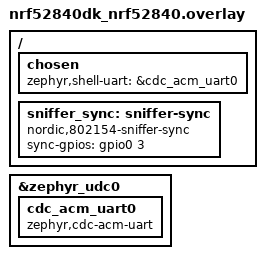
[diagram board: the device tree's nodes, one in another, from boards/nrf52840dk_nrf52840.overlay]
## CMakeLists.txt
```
#
# Copyright (c) 2023 Nordic Semiconductor
#
# SPDX-License-Identifier: LicenseRef-Nordic-5-Clause
#

cmake_minimum_required(VERSION 3.20.0)

list(APPEND DTS_ROOT ${CMAKE_CURRENT_SOURCE_DIR})

find_package(Zephyr REQUIRED HINTS $ENV{ZEPHYR_BASE})
project(802154_sniffer)

target_sources(app PRIVATE
	src/main.c
	src/sniffer_uart.c
)
```

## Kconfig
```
#
# Copyright (c) 2026 Nordic Semiconductor ASA
#
# SPDX-License-Identifier: LicenseRef-Nordic-5-Clause
#

mainmenu "IEEE 802.15.4 Sniffer sample"

config IEEE802154_SNIFFER_TIME_SYNC
	bool "Hardware GPIO time synchronization"
	select NRFX_GPIOTE
	select NRFX_GPPI
	# Only the nRF52 and nRF53 path drives the pulse from a TIMER instance,
	# nRF54L uses GRTC.
	select NRFX_TIMER if !SOC_SERIES_NRF54L
	default y if $(dt_nodelabel_enabled,sniffer_sync)
	help
	  Enable GPIOTE + PPI + GRTC/RTC capture based time sync between
	  multiple sniffer devices. Requires sniffer_sync devicetree node.

config IEEE802154_SNIFFER_SYNC_INTERVAL_MS
	int "Primary sync pulse interval (ms)"
	default 100
	range 10 60000
	depends on IEEE802154_SNIFFER_TIME_SYNC
	help
	  Interval between the sync pulses of the primary device. The lower bound
	  leaves room for the pulse to be cleared from a workqueue item before the
	  next one is due.

config IEEE802154_SNIFFER_SYNC_PULSE_US
	int "Primary sync pulse width (us)"
	default 10
	depends on IEEE802154_SNIFFER_TIME_SYNC
	help
	  Requested width of the sync pulse. Only the rising edge is generated in
	  hardware, while the pin is cleared from a workqueue item, so the pulse is
	  at least one system tick wide (about 30 us) regardless of this value.

config IEEE802154_SNIFFER_UART_BUFFER_SIZE
	int "Capture output buffer size (bytes)"
	default 131072
	help
	  Size of the ring buffer holding capture lines that are waiting for the
	  UART.

config IEEE802154_SNIFFER_UART_BUFFER_LARGE
	bool
	default y if IEEE802154_SNIFFER_UART_BUFFER_SIZE > 32767
	select RING_BUFFER_LARGE
	help
	  Ring buffers above 32 kB need 32 bit indices.

source "Kconfig.zephyr"
```

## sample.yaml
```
sample:
  description: IEEE 802.15.4 Sniffer sample
  name: IEEE 802.15.4 Sniffer
tests:
  sample.peripheral.802154_sniffer:
    sysbuild: true
    build_only: true
    integration_platforms:
      - nrf52840dk/nrf52840
      - nrf52840dongle/nrf52840
      - nrf54lm20dongle/nrf54lm20b/cpuapp
    platform_allow:
      - nrf52840dk/nrf52840
      - nrf52840dongle/nrf52840
      - nrf54lm20dongle/nrf54lm20b/cpuapp
    tags:
      - ci_build
      - sysbuild
      - ci_samples_peripheral_802154
  sample.peripheral.802154_sniffer.no_time_sync:
    sysbuild: true
    build_only: true
    extra_configs:
      - CONFIG_IEEE802154_SNIFFER_TIME_SYNC=n
    integration_platforms:
      - nrf52840dk/nrf52840
    platform_allow:
      - nrf52840dk/nrf52840
    tags:
      - ci_build
      - sysbuild
      - ci_samples_peripheral_802154
```

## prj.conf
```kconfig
# Enabling radio driver
CONFIG_NETWORKING=y
CONFIG_IEEE802154=y
CONFIG_IEEE802154_RAW_MODE=y
CONFIG_NET_PKT_TIMESTAMP=y

# Allow sharing the RTC between IEEE 802.15.4 and Zephyr
CONFIG_NRF_RTC_TIMER_USER_CHAN_COUNT=3

# Increase the number of RX buffers to minimize the chances of frame drops.
# The value must not be higher than 127 - X, where X is the number of notification
# slots reserved by the radio driver (see NTF_PRIMARY_POOL_SIZE macro definition).
CONFIG_NRF_802154_RX_BUFFERS=120

# Capture output encoding. Base64 needs a third fewer bytes than hex.
CONFIG_BASE64=y

# The capture buffer in sniffer_uart.c uses the ring buffer API directly.
CONFIG_RING_BUFFER=y

# Shell configuration
CONFIG_SHELL=y
CONFIG_SHELL_PROMPT_UART=""
CONFIG_SHELL_VT100_COLORS=n

# Sync lines are prioritized only while they sit in the sniffer ring buffer;
# once handed to the backend they queue behind the frame data in FIFO order.
# Keep this buffer small, so that it only has to keep the USB endpoint busy,
# and let the sniffer ring absorb the bursts.
CONFIG_SHELL_BACKEND_SERIAL_TX_RING_BUFFER_SIZE=2048

# Keep USB transfer handling off the system workqueue, which also runs the
# time sync reporting work.
CONFIG_USBD_CDC_ACM_WORKQUEUE=y

# The radio RX thread formats and queues every capture line, which needs more
# stack than the 800 bytes the driver defaults to.
CONFIG_IEEE802154_NRF5_RX_STACK_SIZE=2048

# LED indication
CONFIG_DK_LIBRARY=y

# USB configuration
CONFIG_UART_LINE_CTRL=y
CONFIG_SHELL_BACKEND_SERIAL_INIT_PRIORITY=51

CONFIG_USB_DEVICE_STACK_NEXT=y
CONFIG_CDC_ACM_SERIAL_INITIALIZE_AT_BOOT=y
CONFIG_CDC_ACM_SERIAL_MANUFACTURER_STRING="Nordic Semiconductor ASA"
CONFIG_CDC_ACM_SERIAL_PRODUCT_STRING="nRF 802154 Sniffer"
CONFIG_CDC_ACM_SERIAL_VID=0x1915
CONFIG_CDC_ACM_SERIAL_PID=0x154b

# Disable boot banner
CONFIG_BOOT_BANNER=n
CONFIG_NCS_BOOT_BANNER=n
```

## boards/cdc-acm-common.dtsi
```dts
/*
 * Copyright (c) 2026 Nordic Semiconductor ASA
 *
 * SPDX-License-Identifier: LicenseRef-Nordic-5-Clause
 *
 * Common CDC ACM UART properties, included by the board overlays.
 *
 * The TX FIFO is deliberately small: it is a strict FIFO, so every queued byte
 * delays the next sync report. Bursts are absorbed by the prioritized sniffer
 * ring buffer instead.
 */

hw-flow-control;
tx-fifo-size = <2048>;
```

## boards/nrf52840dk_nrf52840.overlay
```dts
/*
 * Copyright (c) 2023 Nordic Semiconductor ASA
 *
 * SPDX-License-Identifier: LicenseRef-Nordic-5-Clause
 */

/ {
	chosen {
		zephyr,shell-uart = &cdc_acm_uart0;
	};

	sniffer_sync: sniffer-sync {
		compatible = "nordic,802154-sniffer-sync";
		/* SYNC PIN: P0.03. */
		sync-gpios = <&gpio0 3 0>;
	};
};

&zephyr_udc0 {
	cdc_acm_uart0: cdc_acm_uart0 {
		compatible = "zephyr,cdc-acm-uart";
		#include "cdc-acm-common.dtsi"
	};
};
```

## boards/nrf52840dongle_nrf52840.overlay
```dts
/*
 * Copyright (c) 2026 Nordic Semiconductor ASA
 *
 * SPDX-License-Identifier: LicenseRef-Nordic-5-Clause
 */

/ {
	sniffer_sync: sniffer-sync {
		compatible = "nordic,802154-sniffer-sync";
		/* SYNC PIN: P0.02. */
		sync-gpios = <&gpio0 2 0>;
	};
};

&board_cdc_acm_uart {
	#include "cdc-acm-common.dtsi"
};
```

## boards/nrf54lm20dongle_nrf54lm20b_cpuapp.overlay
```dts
/*
 * Copyright (c) 2026 Nordic Semiconductor ASA
 *
 * SPDX-License-Identifier: LicenseRef-Nordic-5-Clause
 */

/ {
	sniffer_sync: sniffer-sync {
		compatible = "nordic,802154-sniffer-sync";
		/* SYNC PIN: P0.03. */
		sync-gpios = <&gpio0 3 0>;
	};
};

&board_cdc_acm_uart {
	#include "cdc-acm-common.dtsi"
};
```

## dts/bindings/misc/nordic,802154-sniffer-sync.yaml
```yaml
# Copyright (c) 2026 Nordic Semiconductor ASA
# SPDX-License-Identifier: LicenseRef-Nordic-5-Clause

description: GPIO pin used for hardware time sync between sniffers

compatible: "nordic,802154-sniffer-sync"

properties:
  sync-gpios:
    type: phandle-array
    required: true
    description: |
      GPIO used for the sync pulse (output on the primary device, input on a
      secondary one).

      Only the port and the pin number are used. The direction follows the role
      selected at runtime, while the pull and the polarity are fixed by the
      capture path (pull-down input, rising edge), so the flags cell is ignored.
```

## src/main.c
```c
/*
 * Copyright (c) 2023 Nordic Semiconductor ASA
 *
 * SPDX-License-Identifier: LicenseRef-Nordic-5-Clause
 */

#include <zephyr/kernel.h>
#include <zephyr/net/ieee802154_radio.h>
#include <zephyr/shell/shell.h>
#include <zephyr/sys/base64.h>
#include <zephyr/sys/util.h>
#include <nrf_802154.h>
#include <nrf_802154_const.h>
#include <stdlib.h>
#include <dk_buttons_and_leds.h>
#include "sniffer_uart.h"

#if IS_ENABLED(CONFIG_IEEE802154_SNIFFER_TIME_SYNC)
#include "time_sync.h"
#endif

#if defined(CONFIG_BOARD_NRF52840DONGLE)
#include <zephyr/drivers/gpio.h>
static const struct device *const gpio_dev = DEVICE_DT_GET(DT_NODELABEL(gpio0));
#endif

#define IEEE802154_FCS_LENGTH 2
#define MAX_PAYLOAD_SIZE (MAX_PACKET_SIZE - IEEE802154_FCS_LENGTH)

/* base64_encode() needs room for the padding and the terminator. */
#define PAYLOAD_STRING_LENGTH (4 * DIV_ROUND_UP(MAX_PAYLOAD_SIZE, 3) + 1)

/* "r " + payload + " -128" + " 255" + " " + 20 digits + CRLF. */
#define MAX_LINE_LENGTH (2 + (PAYLOAD_STRING_LENGTH - 1) + 5 + 4 + 21 + 2)
BUILD_ASSERT(MAX_LINE_LENGTH <= SNIFFER_UART_LINE_MAX,
	     "capture line does not fit in the sniffer UART line buffer");

/* The nRF54L radio reports the RX timestamp of a frame this many microseconds
 * earlier than the nRF52 one. The measured constant is added back so that
 * captures from both merge onto a single timeline.
 */
#define NRF54L_RX_TIMESTAMP_BIAS_US 10

static const struct device *radio_dev =
	DEVICE_DT_GET(DT_CHOSEN(zephyr_ieee802154));
static struct ieee802154_radio_api *radio_api;
static char payload_string[PAYLOAD_STRING_LENGTH];
static bool heartbeat_led_state;
static bool packet_led_state;
static k_timeout_t heartbeat_interval;

static void heartbeat(struct k_work *work);

static K_WORK_DELAYABLE_DEFINE(heartbeat_work, heartbeat);

static void heartbeat(struct k_work *work)
{
	ARG_UNUSED(work);

	heartbeat_led_state = !heartbeat_led_state;
	dk_set_led(DK_LED1, heartbeat_led_state);
	k_work_reschedule(&heartbeat_work, heartbeat_interval);
}

enum net_verdict ieee802154_handle_ack(struct net_if *iface,
				       struct net_pkt *pkt)
{
	ARG_UNUSED(iface);
	ARG_UNUSED(pkt);

	return NET_DROP;
}

int net_recv_data(struct net_if *iface, struct net_pkt *pkt)
{
	if (!pkt) {
		return -EINVAL;
	}

	if (net_pkt_is_empty(pkt)) {
		return -ENODATA;
	}

	uint8_t *psdu = net_buf_frag_last(pkt->buffer)->data;
	size_t length = net_buf_frags_len(pkt->buffer);
	uint8_t lqi = net_pkt_ieee802154_lqi(pkt);
	int8_t rssi = net_pkt_ieee802154_rssi_dbm(pkt);
	struct net_ptp_time *pkt_time = net_pkt_timestamp(pkt);
	uint64_t timestamp =
		pkt_time->second * USEC_PER_SEC + pkt_time->nanosecond / NSEC_PER_USEC;
	size_t encoded;

#if defined(CONFIG_SOC_SERIES_NRF54L)
	timestamp += NRF54L_RX_TIMESTAMP_BIAS_US;
#endif

	/* The radio has already verified the FCS and the host discards it, so it
	 * is not worth transmitting.
	 */
	if (length <= IEEE802154_FCS_LENGTH) {
		net_pkt_unref(pkt);
		return -EINVAL;
	}
	length -= IEEE802154_FCS_LENGTH;

	if (base64_encode(payload_string, sizeof(payload_string), &encoded, psdu, length) != 0) {
		net_pkt_unref(pkt);
		return -ENOMEM;
	}

	packet_led_state = !packet_led_state;
	dk_set_led(DK_LED4, packet_led_state);

	sniffer_uart_emit("r %s %d %u %llu", payload_string, rssi, lqi, timestamp);

	net_pkt_unref(pkt);

	return 0;
}

static int cmd_channel(const struct shell *shell, size_t argc, char **argv)
{
	uint32_t channel;
	int err;

	switch (argc) {
	case 1:
		shell_print(shell, "%d", nrf_802154_channel_get());
		break;
	case 2:
		channel = atoi(argv[1]);
		err = radio_api->set_channel(radio_dev, channel);
		if (err != 0) {
			shell_error(shell, "invalid channel: %s (use 11 to 26)", argv[1]);
			return err;
		}
		break;
	default:
		shell_print(shell, "invalid number of parameters: %d", argc);
		break;
	}

	return 0;
}
SHELL_CMD_ARG_REGISTER(channel, NULL, "Set radio channel", cmd_channel, 1, 1);

#if NRF_802154_GFSK_2MBPS_PHY_ENABLED
static int cmd_phy(const struct shell *shell, size_t argc, char **argv)
{
	ARG_UNUSED(argc);

	nrf_802154_phy_t phy;

	if (strcmp(argv[1], "2m") == 0) {
		phy = NRF_802154_PHY_EXP1_GFSK_2MBPS;
	} else if (strcmp(argv[1], "250k") == 0) {
		phy = NRF_802154_PHY_OQPSK_250KBPS;
	} else {
		shell_error(shell, "unknown phy: %s (use 2m or 250k)", argv[1]);
		return -EINVAL;
	}

	nrf_802154_phy_set(phy);

	return 0;
}

SHELL_CMD_ARG_REGISTER(phy, NULL, "Set radio PHY <2m|250k>", cmd_phy, 2, 0);
#endif /* NRF_802154_GFSK_2MBPS_PHY_ENABLED */

static int cmd_receive(const struct shell *shell, size_t argc, char **argv)
{
	ARG_UNUSED(shell);
	ARG_UNUSED(argc);
	ARG_UNUSED(argv);

	heartbeat_interval = K_MSEC(250);
	radio_api->start(radio_dev);

	return 0;
}
SHELL_CMD_ARG_REGISTER(receive, NULL, "Put radio in receive state", cmd_receive, 1, 0);

static int cmd_sleep(const struct shell *shell, size_t argc, char **argv)
{
	ARG_UNUSED(shell);
	ARG_UNUSED(argc);
	ARG_UNUSED(argv);

#if IS_ENABLED(CONFIG_IEEE802154_SNIFFER_TIME_SYNC)
	time_sync_stop();
#endif

	heartbeat_interval = K_SECONDS(1);
	radio_api->stop(radio_dev);

	return 0;
}
SHELL_CMD_ARG_REGISTER(sleep, NULL, "Disable the radio", cmd_sleep, 1, 0);

#if IS_ENABLED(CONFIG_IEEE802154_SNIFFER_TIME_SYNC)
static int cmd_sync_stop(const struct shell *shell, size_t argc, char **argv)
{
	ARG_UNUSED(argc);
	ARG_UNUSED(argv);

	time_sync_stop();
	shell_print(shell, "sync stopped");
	return 0;
}

static int cmd_sync_primary_start(const struct shell *shell, size_t argc, char **argv)
{
	uint32_t interval_ms = CONFIG_IEEE802154_SNIFFER_SYNC_INTERVAL_MS;
	int err = 0;

	if (argc >= 2) {
		interval_ms = (uint32_t)shell_strtoul(argv[1], 10, &err);
		if (err != 0) {
			shell_error(shell, "invalid interval: %s", argv[1]);
			return -EINVAL;
		}
	}

	err = time_sync_primary_start(interval_ms);
	if (err != 0) {
		shell_error(shell, "sync primary start failed: %d", err);
		return err;
	}

	shell_print(shell, "sync primary started interval_ms=%u", interval_ms);
	return 0;
}

static int cmd_sync_secondary(const struct shell *shell, size_t argc, char **argv)
{
	unsigned long sniffer_id = 1;
	int err = 0;

	if (argc >= 2) {
		sniffer_id = shell_strtoul(argv[1], 10, &err);
		if (err != 0 || sniffer_id > UINT8_MAX) {
			shell_error(shell, "invalid id: %s (use 0 to %u)", argv[1], UINT8_MAX);
			return -EINVAL;
		}
	}

	err = time_sync_secondary_start((uint8_t)sniffer_id);
	if (err != 0) {
		shell_error(shell, "sync secondary start failed: %d", err);
		return err;
	}

	shell_print(shell, "sync secondary started id=%u", (uint8_t)sniffer_id);
	return 0;
}

SHELL_STATIC_SUBCMD_SET_CREATE(
	sub_sync_primary,
	SHELL_CMD_ARG(start, NULL,
		      "sync primary start [interval_ms]",
		      cmd_sync_primary_start, 1, 1),
	SHELL_SUBCMD_SET_END);

SHELL_STATIC_SUBCMD_SET_CREATE(
	sub_sync,
	SHELL_CMD(primary, &sub_sync_primary, "Primary sync role", NULL),
	SHELL_CMD_ARG(secondary, NULL,
		      "Start sync secondary [id]",
		      cmd_sync_secondary, 1, 1),
	SHELL_CMD_ARG(stop, NULL, "Stop time sync", cmd_sync_stop, 1, 0),
	SHELL_SUBCMD_SET_END);

SHELL_CMD_REGISTER(sync, &sub_sync, "Hardware time sync commands", NULL);
#endif /* CONFIG_IEEE802154_SNIFFER_TIME_SYNC */

#if defined(CONFIG_BOARD_NRF52840DONGLE)
static int cmd_bootloader(const struct shell *shell, size_t argc, char **argv)
{
	/*
	 * nRF52840 dongle has pin P0.19 connected to reset. By setting it
	 * in `GPIO_OUTPUT_LOW` mode, reset is pulled to GND,
	 * which results in device rebooting without skipping the bootloader.
	 */
	ARG_UNUSED(shell);
	ARG_UNUSED(argc);
	ARG_UNUSED(argv);

	if (!device_is_ready(gpio_dev)) {
		shell_print(shell, "GPIO device not ready");
		return 0;
	}

	int err = gpio_pin_configure(gpio_dev, 19, GPIO_OUTPUT_LOW);

	if (err) {
		shell_print(shell, "Failed to configure GPIO pin. Error code: %d", err);
	}

	return 0;
}
SHELL_CMD_ARG_REGISTER(bootloader, NULL, "Reboot into bootloader", cmd_bootloader, 1, 0);
#endif /* CONFIG_BOARD_NRF52840DONGLE */

int main(void)
{
	(void)dk_leds_init();

	sniffer_uart_init();
	heartbeat_interval = K_SECONDS(1);
	k_work_reschedule(&heartbeat_work, heartbeat_interval);

	struct ieee802154_config config = {
		.promiscuous = true
	};

	radio_api = (struct ieee802154_radio_api *)radio_dev->api;
	__ASSERT_NO_MSG(radio_api);

#if !IS_ENABLED(CONFIG_NRF_802154_SERIALIZATION)
	/* The serialization API does not support disabling the auto-ack. */
	nrf_802154_auto_ack_set(false);
#endif

	radio_api->configure(radio_dev, IEEE802154_CONFIG_PROMISCUOUS, &config);

	return 0;
}
```

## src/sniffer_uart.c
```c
/*
 * Copyright (c) 2026 Nordic Semiconductor ASA
 *
 * SPDX-License-Identifier: LicenseRef-Nordic-5-Clause
 */

#include "sniffer_uart.h"

#include <errno.h>
#include <stddef.h>
#include <stdarg.h>

#include <zephyr/kernel.h>
#include <zephyr/device.h>
#include <zephyr/drivers/uart.h>
#include <zephyr/shell/shell.h>
#include <zephyr/shell/shell_uart.h>
#include <zephyr/sys/ring_buffer.h>

#define SNIFFER_UART_SYNC_QUEUE_DEPTH 16
#define SNIFFER_UART_DATA_DRAIN_BATCH 4
#define SNIFFER_UART_DRAIN_STACK_SIZE 2048
#define SNIFFER_UART_SHELL_LOCK_MS 50
#define SNIFFER_UART_LINE_TX_TIMEOUT_MS 100

struct sniffer_uart_line {
	uint16_t len;
	char data[SNIFFER_UART_LINE_MAX];
};

/* Packet lines are stored as length prefixed records in a byte ring buffer. */
BUILD_ASSERT(offsetof(struct sniffer_uart_line, data) == sizeof(uint16_t),
	     "line length prefix must be contiguous with the payload");

static struct k_msgq sync_msgq;
static char __aligned(4) sync_msgq_buffer[SNIFFER_UART_SYNC_QUEUE_DEPTH *
					   sizeof(struct sniffer_uart_line)];

RING_BUF_DECLARE(data_rb, CONFIG_IEEE802154_SNIFFER_UART_BUFFER_SIZE);

static const struct device *const shell_uart_dev = DEVICE_DT_GET(DT_CHOSEN(zephyr_shell_uart));
static const struct shell *uart_shell;
static struct k_mutex format_lock;
static struct sniffer_uart_line format_line;
static struct k_sem drain_wake;
static struct k_thread drain_thread;
static K_KERNEL_STACK_MEMBER(drain_stack, SNIFFER_UART_DRAIN_STACK_SIZE);

static bool host_port_ready(void)
{
	int dtr = 0;

	if (!IS_ENABLED(CONFIG_UART_LINE_CTRL) || !device_is_ready(shell_uart_dev)) {
		return true;
	}

	if (uart_line_ctrl_get(shell_uart_dev, UART_LINE_CTRL_DTR, &dtr) != 0) {
		/* Plain UART backend - no host-side flow information. */
		return true;
	}

	return dtr != 0;
}

/* shell_fprintf() would block the drain thread on the TXDONE signal that only the shell
 * thread services, so lines are written through the transport under ctx->lock_sem, the
 * semaphore behind z_shell_lock().
 */
static bool shell_tx_lock(void)
{
	if (uart_shell == NULL || uart_shell->ctx == NULL) {
		return false;
	}

	return k_sem_take(&uart_shell->ctx->lock_sem, K_MSEC(SNIFFER_UART_SHELL_LOCK_MS)) == 0;
}

static void shell_tx_unlock(void)
{
	if (uart_shell != NULL && uart_shell->ctx != NULL) {
		k_sem_give(&uart_shell->ctx->lock_sem);
	}
}

struct drain_slot {
	struct sniffer_uart_line line;
	bool valid;
};

/* The backend accepts only what currently fits in its ring buffer, so a line
 * can be split. Releasing the lock in between would let a sync line or a shell
 * response land in the middle of the frame, so the lock is held until the line
 * is complete. The deadline bounds how long that blocks shell commands when the
 * host stops draining the port.
 */
static size_t shell_tx_write_line(const struct sniffer_uart_line *line)
{
	const struct shell_transport *iface = uart_shell->iface;
	k_timepoint_t deadline = sys_timepoint_calc(K_MSEC(SNIFFER_UART_LINE_TX_TIMEOUT_MS));
	size_t offset = 0;

	while (offset < line->len) {
		size_t cnt = 0;

		if (iface->api->write(iface, &line->data[offset],
				      line->len - offset, &cnt) != 0) {
			break;
		}

		offset += cnt;

		if (offset == 0) {
			break;
		}

		if (offset < line->len) {
			if (sys_timepoint_expired(deadline) || !host_port_ready()) {
				break;
			}
			k_msleep(1);
		}
	}

	return offset;
}

static int uart_format_line(struct sniffer_uart_line *line, const char *fmt, va_list args)
{
	int len;

	len = vsnprintk(line->data, sizeof(line->data) - 2, fmt, args);
	if (len <= 0) {
		return -EINVAL;
	}

	len = MIN(len, (int)sizeof(line->data) - 3);

	if (len >= 2 && line->data[len - 2] == '\r' && line->data[len - 1] == '\n') {
		line->len = len;
	} else if (len >= 1 && line->data[len - 1] == '\n') {
		line->data[len - 1] = '\r';
		line->data[len++] = '\n';
		line->len = len;
	} else {
		line->data[len++] = '\r';
		line->data[len++] = '\n';
		line->len = len;
	}

	return 0;
}

/* ring_buf_put() commits the whole record with one ring_buf_put_finish(),
 * so the consumer never observes a half written line.
 */
static bool data_rb_put(const struct sniffer_uart_line *line)
{
	uint32_t record = sizeof(line->len) + line->len;

	if (ring_buf_space_get(&data_rb) < record) {
		return false;
	}

	return ring_buf_put(&data_rb, (const uint8_t *)&line->len, record) == record;
}

static bool data_rb_get(struct sniffer_uart_line *line)
{
	uint16_t len;

	if (ring_buf_get(&data_rb, (uint8_t *)&len, sizeof(len)) != sizeof(len)) {
		return false;
	}

	/* Bounds the copy into the fixed size line buffer. */
	if (len > SNIFFER_UART_LINE_MAX ||
	    ring_buf_get(&data_rb, (uint8_t *)line->data, len) != len) {
		return false;
	}

	line->len = len;

	return true;
}

static void uart_emit_common(bool sync, const char *fmt, va_list args)
{
	bool queued;

	k_mutex_lock(&format_lock, K_FOREVER);
	if (uart_format_line(&format_line, fmt, args) != 0) {
		k_mutex_unlock(&format_lock);
		return;
	}

	if (sync) {
		queued = k_msgq_put(&sync_msgq, &format_line, K_NO_WAIT) == 0;
		if (!queued) {
			struct sniffer_uart_line dropped;

			(void)k_msgq_get(&sync_msgq, &dropped, K_NO_WAIT);
			queued = k_msgq_put(&sync_msgq, &format_line, K_NO_WAIT) == 0;
		}
	} else {
		queued = data_rb_put(&format_line);
	}
	k_mutex_unlock(&format_lock);

	if (!queued) {
		return;
	}

	k_sem_give(&drain_wake);
}

static struct drain_slot sync_slot;
static struct drain_slot data_slot;

static bool slot_load(struct drain_slot *slot, bool sync)
{
	if (sync) {
		return k_msgq_get(&sync_msgq, &slot->line, K_NO_WAIT) == 0;
	}

	return data_rb_get(&slot->line);
}

static bool drain_line(struct drain_slot *slot, bool sync)
{
	if (!slot->valid) {
		if (!slot_load(slot, sync)) {
			return false;
		}
		slot->valid = true;

		if (!host_port_ready()) {
			slot->valid = false;
			return true;
		}
	}

	if (!shell_tx_lock()) {
		return false;
	}

	size_t written = shell_tx_write_line(&slot->line);

	shell_tx_unlock();

	if (written == 0) {
		return false;
	}

	/* A line that was cut short cannot be resumed once the lock is released,
	 * so drop the remainder instead of duplicating the prefix.
	 */
	slot->valid = false;

	return true;
}

static bool drain_pending(void)
{
	return sync_slot.valid || data_slot.valid ||
	       k_msgq_num_used_get(&sync_msgq) > 0 ||
	       !ring_buf_is_empty(&data_rb);
}

static bool drain_once(void)
{
	unsigned int data_drained = 0;

	while (sync_slot.valid || k_msgq_num_used_get(&sync_msgq) > 0) {
		if (!drain_line(&sync_slot, true)) {
			return false;
		}
	}

	while (data_drained < SNIFFER_UART_DATA_DRAIN_BATCH &&
	       (data_slot.valid || !ring_buf_is_empty(&data_rb))) {
		if (!drain_line(&data_slot, false)) {
			return false;
		}
		data_drained++;
	}

	return true;
}

static void drain_thread_entry(void *p1, void *p2, void *p3)
{
	ARG_UNUSED(p1);
	ARG_UNUSED(p2);
	ARG_UNUSED(p3);

	while (true) {
		(void)k_sem_take(&drain_wake, K_FOREVER);

		while (drain_pending()) {
			if (drain_once()) {
				k_yield();
			} else {
				/* Shell TX is busy elsewhere, back off instead of spinning. */
				k_msleep(1);
			}
		}
	}
}

void sniffer_uart_init(void)
{
	k_mutex_init(&format_lock);
	k_msgq_init(&sync_msgq, sync_msgq_buffer, sizeof(struct sniffer_uart_line),
		    SNIFFER_UART_SYNC_QUEUE_DEPTH);
	k_sem_init(&drain_wake, 0, 1);

	uart_shell = shell_backend_uart_get_ptr();

	k_thread_create(&drain_thread, drain_stack, K_KERNEL_STACK_SIZEOF(drain_stack),
			drain_thread_entry, NULL, NULL, NULL, K_LOWEST_APPLICATION_THREAD_PRIO, 0,
			K_NO_WAIT);
	k_thread_name_set(&drain_thread, "sniffer_uart");
}

void sniffer_uart_emit(const char *fmt, ...)
{
	va_list args;

	va_start(args, fmt);
	uart_emit_common(false, fmt, args);
	va_end(args);
}

void sniffer_uart_emit_sync(const char *fmt, ...)
{
	va_list args;

	va_start(args, fmt);
	uart_emit_common(true, fmt, args);
	va_end(args);
}
```

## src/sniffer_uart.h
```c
/*
 * Copyright (c) 2026 Nordic Semiconductor ASA
 *
 * SPDX-License-Identifier: LicenseRef-Nordic-5-Clause
 */

#ifndef SNIFFER_UART_H_
#define SNIFFER_UART_H_

#include <stdint.h>

/** Maximum length of one emitted line, including the CRLF terminator.
 *
 * The longest line carries a maximum size frame without its FCS, which is 253
 * bytes and 340 base64 characters, plus about 30 characters of metadata.
 */
#define SNIFFER_UART_LINE_MAX 384

void sniffer_uart_init(void);

/** Packet lines. Dropped when the buffer is full, and discarded rather than
 * queued while the host keeps the port closed.
 */
void sniffer_uart_emit(const char *fmt, ...);

/** Sync lines: drained before packet lines, and when the sync queue is full the
 * oldest pending sync line is evicted rather than the new one.
 */
void sniffer_uart_emit_sync(const char *fmt, ...);

#endif /* SNIFFER_UART_H_ */
```

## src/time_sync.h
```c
/*
 * Copyright (c) 2026 Nordic Semiconductor ASA
 *
 * SPDX-License-Identifier: LicenseRef-Nordic-5-Clause
 */

#ifndef TIME_SYNC_H_
#define TIME_SYNC_H_

#include <stdint.h>

int time_sync_primary_start(uint32_t interval_ms);

int time_sync_secondary_start(uint8_t sniffer_id);

void time_sync_stop(void);

#endif /* TIME_SYNC_H_ */
```
